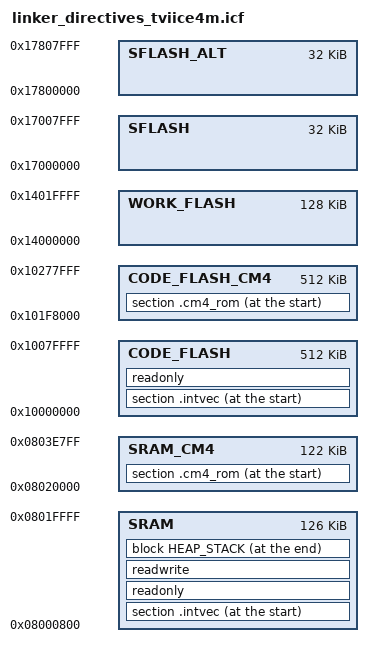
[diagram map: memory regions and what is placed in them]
/***************************************************************************//**
* \file linker_directives_tviice4m.icf
* \version 1.0
*
* \brief Linker file for the IAR compiler.
*
*
********************************************************************************
* \copyright
* Copyright 2017, Cypress Semiconductor Corporation.  All rights reserved.
* You may use this file only in accordance with the license, terms, conditions,
* disclaimers, and limitations in the end user license agreement accompanying
* the software package with which this file was provided.
*******************************************************************************/

define symbol use_psvp                          = 1; // 0 - Silicon, 1 - PSVP

// Check that necessary symbols have been passed to linker via command line interface
if((!isdefinedsymbol(_LINK_sram_)) && (!isdefinedsymbol(_LINK_flash_))) {
  error "Link location not defined or not supported!";
}
if((!isdefinedsymbol(_CORE_cm0plus_)) && (!isdefinedsymbol(_CORE_cm4_))) {
  error "Core type not defined or not supported!";
}

//============================================================
// Memory address and size definitions
//============================================================

// Specify how much SRAM and CODE_FLASH (starting from the first address of the respective memory) shall
// be used by CM0+ application, the rest of the memory will be automatically assigned to CM4 application

define symbol sram_total_size                   = 256K;
define symbol sram_private_for_srom             =   2K; // Private SRAM for SROM (e.g. API processing). Reserved at the beginning.
// Used during boot by Cypress firmware 
// (content will be overwritten on reset, so it should not be used for loadable sections in case of RAM build configurations)
// SRAM_MAX-4KB to SRAM_MAX-2KB is only affected
define symbol sram_used_by_boot                 =   6K; 

define symbol cm0plus_sram_reserve              = 128K; 
// define symbol cm4_sram_reserve               = sram_total_size - cm0plus_sram_reserve; 

if(use_psvp == 1)
{
    // PSVP
    define symbol code_flash_total_size         =  1024K;
    define symbol cm0plus_code_flash_reserve    =  512K;
    define symbol cm4_code_flash_reserve        =  code_flash_total_size - cm0plus_code_flash_reserve;
}
else 
{
    // Silicon
    define symbol code_flash_total_size         = 4160K;
    define symbol cm0plus_code_flash_reserve    =  512K;
    // define symbol cm4_code_flash_reserve     = 3648K; // 4160K-512K = 3648K
}


define symbol code_flash_base_address           = 0x10000000;
define symbol sram_base_address                 = 0x08000000;

define symbol ecc_init_width                    = 8; // Most restrictive native ECC width of all "normal" memories (SRAM, DTCM, ITCM) in any Traveo II derivate is used to keep the code generic

//----------------------------------------------

// Specify stack and heap sizes for CM0+ and CM4 application independently
define symbol cm0plus_heap_reserve              = 1K;
define symbol cm0plus_stack_reserve             = 2K;
define symbol cm4_heap_reserve                  = 1K;
define symbol cm4_stack_reserve                 = 8K;

// Map core dependent definition to generic symbol for block definition
if(isdefinedsymbol(_CORE_cm0plus_)) {
    define symbol heap_reserve  = cm0plus_heap_reserve;
    define symbol stack_reserve = (cm0plus_stack_reserve + (ecc_init_width - 1)) & (~((ecc_init_width - 1))); // Ensure that stack size is an integer multiple of ECC init width (round up)
} else { // CM4
    define symbol heap_reserve  = cm4_heap_reserve;
    define symbol stack_reserve = (cm4_stack_reserve     + (ecc_init_width - 1)) & (~((ecc_init_width - 1))); // Ensure that stack size is an integer multiple of ECC init width (round up)
}

if(isdefinedsymbol(_LINK_sram_))
{
    // Subtract 'sram_used_by_boot' beause content will be overwritten on reset, so it should not be used for loadable sections of RAM build configurations, which are only downloaded once by debugger)
    // Note: Could be removed if you ensure that no loadable section types (e.g. .text or .rodata) would be linked to this area
    define symbol sram_total_size_user       = sram_total_size - sram_used_by_boot;
} 
else 
{
    // Please note that 'sram_used_by_boot' is not subtracted from total size, but will have to be considered if certain sections need to preserve their content over a boot cycle
    define symbol sram_total_size_user       = sram_total_size;
} 

//----------------------------------------------
//----------------------------------------------

// CM4 definitions are required in CM0+ linker script for assigning the CM4 binary further below. (IAR multi core debugging)

// SRAM reservations
define symbol _base_SRAM_CM0P                   = sram_base_address + sram_private_for_srom;
define symbol _size_SRAM_CM0P                   = cm0plus_sram_reserve - sram_private_for_srom;
define symbol _base_SRAM_CM4                    = sram_base_address + cm0plus_sram_reserve;
define symbol _size_SRAM_CM4                    = sram_total_size_user - cm0plus_sram_reserve;

// Code flash reservations
define symbol _base_CODE_FLASH_CM0P             = code_flash_base_address;
define symbol _size_CODE_FLASH_CM0P             = cm0plus_code_flash_reserve;
if(use_psvp)
{
    define symbol _base_CODE_FLASH_CM4          = 0x101F8000;
    define symbol _size_CODE_FLASH_CM4          = cm4_code_flash_reserve;
}
else
{
    define symbol _base_CODE_FLASH_CM4          = code_flash_base_address + cm0plus_code_flash_reserve;
    define symbol _size_CODE_FLASH_CM4          = code_flash_total_size - cm0plus_code_flash_reserve;
}

if(isdefinedsymbol(_CORE_cm0plus_)) {
    define symbol _base_SRAM                    = _base_SRAM_CM0P;
    define symbol _size_SRAM                    = _size_SRAM_CM0P;
    define symbol _base_CODE_FLASH              = _base_CODE_FLASH_CM0P;
    define symbol _size_CODE_FLASH              = _size_CODE_FLASH_CM0P;   
} else { // CM4
    // Re-use existing symbols from above and map them to the generic name
    define symbol _base_SRAM                    = _base_SRAM_CM4;
    define symbol _size_SRAM                    = _size_SRAM_CM4;
    define symbol _base_CODE_FLASH              = _base_CODE_FLASH_CM4;
    define symbol _size_CODE_FLASH              = _size_CODE_FLASH_CM4;
}

define symbol _base_WORK_FLASH                  = 0x14000000;
define symbol _size_WORK_FLASH                  = 0x00020000; // 128 KB
define symbol _base_SFLASH                      = 0x17000000;
define symbol _size_SFLASH                      = 0x00008000; //  32 KB
define symbol _base_SFLASH_ALT                  = 0x17800000;
define symbol _size_SFLASH_ALT                  = 0x00008000; //  32 KB

//============================================================
// Memory definitions
//============================================================

define memory mem with size = 4G;

define region SRAM                              = mem:[from _base_SRAM               size _size_SRAM           ];
define region CODE_FLASH                        = mem:[from _base_CODE_FLASH         size _size_CODE_FLASH     ];
define region WORK_FLASH                        = mem:[from _base_WORK_FLASH         size _size_WORK_FLASH     ];
define region SFLASH                            = mem:[from _base_SFLASH             size _size_SFLASH         ];
define region SFLASH_ALT                        = mem:[from _base_SFLASH_ALT         size _size_SFLASH_ALT     ];

// CM4 regions are required in CM0+ linker script for assigning the CM4 binary further below. (IAR multi core debugging)
if(isdefinedsymbol(_CORE_cm0plus_)) {
    define region SRAM_CM4       = mem:[from _base_SRAM_CM4           size _size_SRAM_CM4       ];
    define region CODE_FLASH_CM4 = mem:[from _base_CODE_FLASH_CM4     size _size_CODE_FLASH_CM4 ];
}

//============================================================
// Block definitions
//============================================================
define block CSTACK         with alignment = 8, size = stack_reserve { };
define block HEAP           with alignment = 8, size = heap_reserve   { };
define block HEAP_STACK     { block HEAP, last block CSTACK };


//============================================================
// Initialization
//============================================================
initialize by copy { readwrite };
do not initialize  { section .intvec_ram };


//============================================================
// Placement
//============================================================

// Link location specific assignment of 'readonly' type sections to either SRAM or CODE_FLASH
// Note: .intvec must be the first section in ROM in order for __cm4_vector_base_linker_symbol to be correctly calculated!
if(isdefinedsymbol(_LINK_flash_)) {
    place at start of CODE_FLASH  { section .intvec };
    place in          CODE_FLASH  { readonly };

    // Include CM4 binary in the CM0+ output. (IAR multi core debugging)
    if(isdefinedsymbol(_CORE_cm0plus_)) {
        place at start of CODE_FLASH_CM4 { section .cm4_rom };
    }
} else if(isdefinedsymbol(_LINK_sram_)) {
    place at start of SRAM  { section .intvec };
    place in          SRAM  { readonly };

    // Include CM4 binary in the CM0+ output. (IAR multi core debugging)
    if(isdefinedsymbol(_CORE_cm0plus_)) {
        place at start of SRAM_CM4 { section .cm4_rom };
    }
}

place in          SRAM  { readwrite };
place at end   of SRAM  { block HEAP_STACK };

//============================================================
// Symbols for use by application
//============================================================
// The start of CM4 vector table is required by CM0+ application to correctly
// set CPUSS->CM4_VECTOR_TABLE_BASE register before releasing CM4 from reset
if(isdefinedsymbol(_CORE_cm0plus_)) {
    if(isdefinedsymbol(_LINK_flash_)) {
        define exported symbol __cm4_vector_base_linker_symbol = start(CODE_FLASH_CM4);
    } else if(isdefinedsymbol(_LINK_sram_)) {
        define exported symbol __cm4_vector_base_linker_symbol = start(SRAM_CM4);
    }
}

// These symbols will be used by startup.c / startup_customize.h for RAM ECC initialisation
if(isdefinedsymbol(_LINK_sram_))
{
    // Following definitions ensure that SRAM will not be touched at all by startup ECC initialization when code is linked to SRAM,
    // use debugger script to initialize the SRAM before downloading the application or adjust below symbols to not include
    // the area of SRAM where "ROM type" sections are linked to 
    define exported symbol __ecc_init_sram_start_address = start(SRAM);
    define exported symbol __ecc_init_sram_end_address   = start(SRAM) - 1;
}
else
{
    define exported symbol __ecc_init_sram_start_address = start(SRAM);
    define exported symbol __ecc_init_sram_end_address   = end(SRAM);
}  

